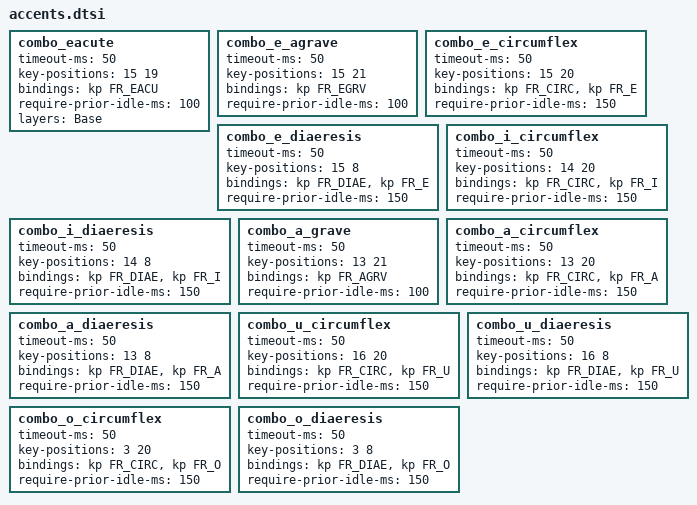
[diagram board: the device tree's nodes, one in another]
// +------------------+------------------+
// | 0  1  2  3  4  5 |  6  7  8  9 10 11|
// |12 13 14 15 16 17 | 18 19 20 21 22 23|
// |24 25 26 27 28 29 | 30 31 32 33 34 35|
// +--------|36 37 38 | 39 40 41|--------+
//          +---------+---------+

// E + T => é
combo_eacute {
    timeout-ms = <50>;           // Délai court pour la détection
    key-positions = <15 19>;       // Positions des touches E et T
    bindings = <&kp FR_EACU>;    // Output du é
    require-prior-idle-ms = <100>;
    // layers = <0 1 2 3 4 5>;
    layers = <Base>;
};

// E + R => è
combo_e_agrave {
    timeout-ms = <50>;           // Délai court pour la détection
    key-positions = <15 21>;       // Positions des touches E et R
    bindings = <&kp FR_EGRV>;    // Output du è
    require-prior-idle-ms = <100>;
};

// E + S => ê
combo_e_circumflex {
    timeout-ms = <50>;
    key-positions = <15 20>;
    bindings = <&kp FR_CIRC>, <&kp FR_E>;
    require-prior-idle-ms = <150>;
};

// E + L => ë
combo_e_diaeresis {
    timeout-ms = <50>;
    key-positions = <15 8>;
    bindings = <&kp FR_DIAE>, <&kp FR_E>;
    require-prior-idle-ms = <150>;
};


// I + S => ê
combo_i_circumflex {
    timeout-ms = <50>;
    key-positions = <14 20>;
    bindings = <&kp FR_CIRC>, <&kp FR_I>;
    require-prior-idle-ms = <150>;
};

// I + L => ï
combo_i_diaeresis {
    timeout-ms = <50>;
    key-positions = <14 8>;
    bindings = <&kp FR_DIAE>, <&kp FR_I>;
    require-prior-idle-ms = <150>;
};


// A + R => à
combo_a_grave {
    timeout-ms = <50>;           // Délai court pour la détection
    key-positions = <13 21>;       // Positions des touches A et R
    bindings = <&kp FR_AGRV>;    // Output du à
    require-prior-idle-ms = <100>;
};

// A + S => â
combo_a_circumflex {
    timeout-ms = <50>;
    key-positions = <13 20>;
    bindings = <&kp FR_CIRC>, <&kp FR_A>;
    require-prior-idle-ms = <150>;
};

// A + L => ä
combo_a_diaeresis {
    timeout-ms = <50>;
    key-positions = <13 8>;
    bindings = <&kp FR_DIAE>, <&kp FR_A>;
    require-prior-idle-ms = <150>;
};


// U + S => û
combo_u_circumflex {
    timeout-ms = <50>;
    key-positions = <16 20>;
    bindings = <&kp FR_CIRC>, <&kp FR_U>;
    require-prior-idle-ms = <150>;
};

// U + L => ü
combo_u_diaeresis {
    timeout-ms = <50>;
    key-positions = <16 8>;
    bindings = <&kp FR_DIAE>, <&kp FR_U>;
    require-prior-idle-ms = <150>;
};


// O + S => Ô
combo_o_circumflex {
    timeout-ms = <50>;
    key-positions = <3 20>;
    bindings = <&kp FR_CIRC &kp FR_O>;
    require-prior-idle-ms = <150>;
};

// O + L => ö
combo_o_diaeresis {
    timeout-ms = <50>;
    key-positions = <3 8>;
    bindings = <&kp FR_DIAE>, <&kp FR_O>;
    require-prior-idle-ms = <150>;
};
